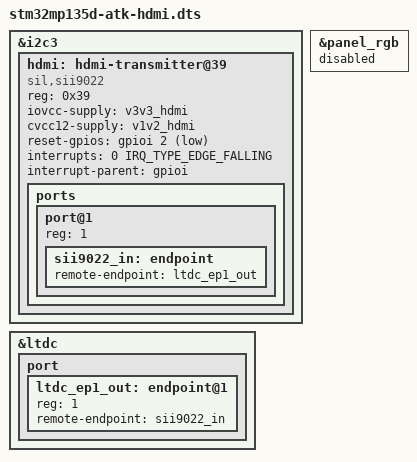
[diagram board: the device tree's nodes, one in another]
/*
 * stm32mp135d-atk-hdmi.dts
 */

#include "stm32mp135d-atk.dts"

&i2c3 {
    hdmi: hdmi-transmitter@39 {
		compatible = "sil,sii9022";
		reg = <0x39>;
		iovcc-supply = <&v3v3_hdmi>;
		cvcc12-supply = <&v1v2_hdmi>;
		reset-gpios = <&gpioi 2 GPIO_ACTIVE_LOW>;
		interrupts = <0 IRQ_TYPE_EDGE_FALLING>;
		interrupt-parent = <&gpioi>;
		status = "okay";

		ports {
			#address-cells = <1>;
			#size-cells = <0>;

			port@1 {
				reg = <1>;
				sii9022_in: endpoint {
					remote-endpoint = <&ltdc_ep1_out>;
				};
			};
		};
	};
};

&panel_rgb {
	status = "disabled";
};

&ltdc {
	port {
		#address-cells = <1>;
		#size-cells = <0>;

		ltdc_ep1_out: endpoint@1 {
			reg = <1>;
			remote-endpoint = <&sii9022_in>;
		};
	};
};
